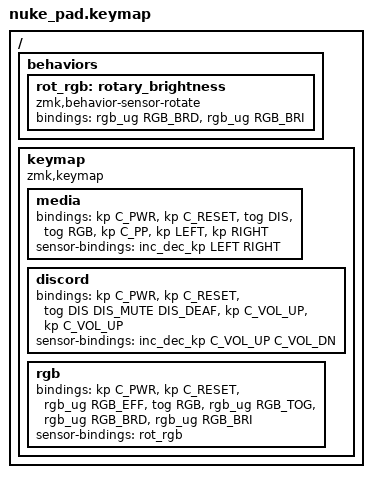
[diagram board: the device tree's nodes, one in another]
#include <behaviors.dtsi>
#include <dt-bindings/zmk/keys.h>
#include <dt-bindings/zmk/rgb.h>

#define MEDIA     0
#define DIS       1
#define RGB       2 
  
#define DIS_MUTE  &kp LC(LS(M))
#define DIS_DEAF  &kp LC(LS(D))

/ {
    behaviors {
        rot_rgb: rotary_brightness {
            compatible = "zmk,behavior-sensor-rotate";
            #sensor-binding-cells = <0>;
            bindings = <&rgb_ug RGB_BRD>, <&rgb_ug RGB_BRI>;
        };
    };
};

/ {
    keymap {
        compatible = "zmk,keymap";
        media {
            bindings = <
                &kp C_PWR         &kp C_RESET         &tog DIS            &tog RGB         &kp C_PP             &kp LEFT         &kp RIGHT
            >;
            sensor-bindings = <&inc_dec_kp LEFT RIGHT>;
        };
        discord {
            bindings = <
                &kp C_PWR         &kp C_RESET         &tog DIS            DIS_MUTE     DIS_DEAF        &kp C_VOL_UP      &kp C_VOL_UP
            >;
            sensor-bindings = <&inc_dec_kp C_VOL_UP C_VOL_DN>;
        };
        rgb {
            bindings = <
                &kp C_PWR         &kp C_RESET         &rgb_ug RGB_EFF     &tog RGB         &rgb_ug RGB_TOG      &rgb_ug RGB_BRD     &rgb_ug RGB_BRI
            >;
            sensor-bindings = <&rot_rgb>;
        };
    };
};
